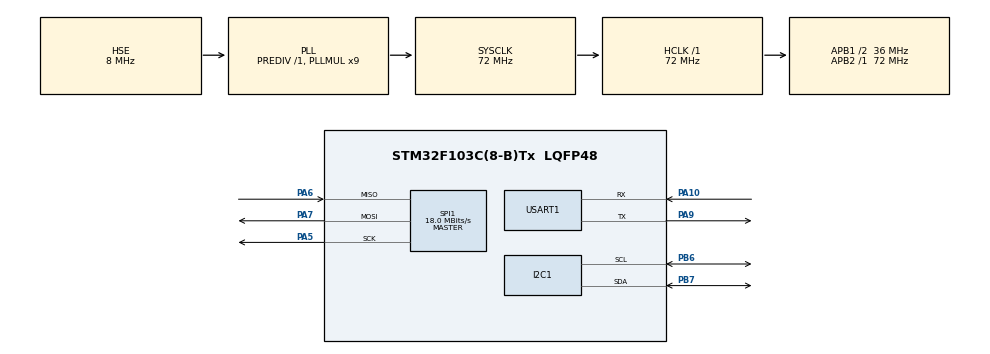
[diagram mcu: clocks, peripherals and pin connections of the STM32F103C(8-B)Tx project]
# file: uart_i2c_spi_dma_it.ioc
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Dma.I2C1_RX.0.Direction=DMA_PERIPH_TO_MEMORY
Dma.I2C1_RX.0.Instance=DMA1_Channel7
Dma.I2C1_RX.0.MemDataAlignment=DMA_MDATAALIGN_BYTE
Dma.I2C1_RX.0.MemInc=DMA_MINC_ENABLE
Dma.I2C1_RX.0.Mode=DMA_NORMAL
Dma.I2C1_RX.0.PeriphDataAlignment=DMA_PDATAALIGN_BYTE
Dma.I2C1_RX.0.PeriphInc=DMA_PINC_DISABLE
Dma.I2C1_RX.0.Priority=DMA_PRIORITY_LOW
Dma.I2C1_TX.1.Direction=DMA_MEMORY_TO_PERIPH
Dma.I2C1_TX.1.Instance=DMA1_Channel6
Dma.I2C1_TX.1.MemDataAlignment=DMA_MDATAALIGN_BYTE
Dma.I2C1_TX.1.MemInc=DMA_MINC_ENABLE
Dma.I2C1_TX.1.Mode=DMA_NORMAL
Dma.I2C1_TX.1.PeriphDataAlignment=DMA_PDATAALIGN_BYTE
Dma.I2C1_TX.1.PeriphInc=DMA_PINC_DISABLE
Dma.I2C1_TX.1.Priority=DMA_PRIORITY_LOW
Dma.Request0=I2C1_RX
Dma.Request1=I2C1_TX
Dma.Request2=USART1_RX
Dma.Request3=USART1_TX
Dma.Request4=SPI1_RX
Dma.Request5=SPI1_TX
Dma.SPI1_RX.4.Direction=DMA_PERIPH_TO_MEMORY
Dma.SPI1_RX.4.Instance=DMA1_Channel2
Dma.SPI1_RX.4.MemDataAlignment=DMA_MDATAALIGN_BYTE
Dma.SPI1_RX.4.MemInc=DMA_MINC_ENABLE
Dma.SPI1_RX.4.Mode=DMA_NORMAL
Dma.SPI1_RX.4.PeriphDataAlignment=DMA_PDATAALIGN_BYTE
Dma.SPI1_RX.4.PeriphInc=DMA_PINC_DISABLE
Dma.SPI1_RX.4.Priority=DMA_PRIORITY_LOW
Dma.SPI1_TX.5.Direction=DMA_MEMORY_TO_PERIPH
Dma.SPI1_TX.5.Instance=DMA1_Channel3
Dma.SPI1_TX.5.MemDataAlignment=DMA_MDATAALIGN_BYTE
Dma.SPI1_TX.5.MemInc=DMA_MINC_ENABLE
Dma.SPI1_TX.5.Mode=DMA_NORMAL
Dma.SPI1_TX.5.PeriphDataAlignment=DMA_PDATAALIGN_BYTE
Dma.SPI1_TX.5.PeriphInc=DMA_PINC_DISABLE
Dma.SPI1_TX.5.Priority=DMA_PRIORITY_LOW
Dma.USART1_RX.2.Direction=DMA_PERIPH_TO_MEMORY
Dma.USART1_RX.2.Instance=DMA1_Channel5
Dma.USART1_RX.2.MemDataAlignment=DMA_MDATAALIGN_BYTE
Dma.USART1_RX.2.MemInc=DMA_MINC_ENABLE
Dma.USART1_RX.2.Mode=DMA_NORMAL
Dma.USART1_RX.2.PeriphDataAlignment=DMA_PDATAALIGN_BYTE
Dma.USART1_RX.2.PeriphInc=DMA_PINC_DISABLE
Dma.USART1_RX.2.Priority=DMA_PRIORITY_LOW
Dma.USART1_TX.3.Direction=DMA_MEMORY_TO_PERIPH
Dma.USART1_TX.3.Instance=DMA1_Channel4
Dma.USART1_TX.3.MemDataAlignment=DMA_MDATAALIGN_BYTE
Dma.USART1_TX.3.MemInc=DMA_MINC_ENABLE
Dma.USART1_TX.3.Mode=DMA_NORMAL
Dma.USART1_TX.3.PeriphDataAlignment=DMA_PDATAALIGN_BYTE
Dma.USART1_TX.3.PeriphInc=DMA_PINC_DISABLE
Dma.USART1_TX.3.Priority=DMA_PRIORITY_LOW
Mcu.Family=STM32F1
Mcu.Name=STM32F103C(8-B)Tx
Mcu.Package=LQFP48
NVIC.DMA1_Channel2_IRQn=true\:0\:0\:false\:false\:true\:false\:true\:true
NVIC.DMA1_Channel3_IRQn=true\:0\:0\:false\:false\:true\:false\:true\:true
NVIC.DMA1_Channel4_IRQn=true\:0\:0\:false\:false\:true\:false\:true\:true
NVIC.DMA1_Channel5_IRQn=true\:0\:0\:false\:false\:true\:false\:true\:true
NVIC.DMA1_Channel6_IRQn=true\:0\:0\:false\:false\:true\:false\:true\:true
NVIC.DMA1_Channel7_IRQn=true\:0\:0\:false\:false\:true\:false\:true\:true
NVIC.I2C1_EV_IRQn=true\:0\:0\:false\:false\:true\:true\:true\:true
NVIC.PriorityGroup=NVIC_PRIORITYGROUP_4
NVIC.SPI1_IRQn=true\:0\:0\:false\:false\:true\:true\:true\:true
NVIC.USART1_IRQn=true\:0\:0\:false\:false\:true\:true\:true\:true
PA10.Mode=Asynchronous
PA10.Signal=USART1_RX
PA13.Mode=Serial_Wire
PA13.Signal=SYS_JTMS-SWDIO
PA14.Mode=Serial_Wire
PA14.Signal=SYS_JTCK-SWCLK
PA5.Mode=Full_Duplex_Master
PA5.Signal=SPI1_SCK
PA6.Mode=Full_Duplex_Master
PA6.Signal=SPI1_MISO
PA7.Mode=Full_Duplex_Master
PA7.Signal=SPI1_MOSI
PA9.Mode=Asynchronous
PA9.Signal=USART1_TX
PB6.Mode=I2C
PB6.Signal=I2C1_SCL
PB7.Mode=I2C
PB7.Signal=I2C1_SDA
PD0-OSC_IN.Mode=HSE-External-Oscillator
PD0-OSC_IN.Signal=RCC_OSC_IN
PD1-OSC_OUT.Mode=HSE-External-Oscillator
PD1-OSC_OUT.Signal=RCC_OSC_OUT
ProjectManager.HeapSize=0x200
ProjectManager.StackSize=0x400
ProjectManager.TargetToolchain=Makefile
RCC.AHBFreq_Value=72000000
RCC.APB1CLKDivider=RCC_HCLK_DIV2
RCC.APB1Freq_Value=36000000
RCC.APB1TimFreq_Value=72000000
RCC.APB2Freq_Value=72000000
RCC.APB2TimFreq_Value=72000000
RCC.HCLKFreq_Value=72000000
RCC.PLLMUL=RCC_PLL_MUL9
RCC.PLLSourceVirtual=RCC_PLLSOURCE_HSE
RCC.SYSCLKFreq_VALUE=72000000
RCC.SYSCLKSource=RCC_SYSCLKSOURCE_PLLCLK
RCC.USBFreq_Value=72000000
SPI1.BaudRatePrescaler=SPI_BAUDRATEPRESCALER_4
SPI1.CalculateBaudRate=18.0 MBits/s
SPI1.Direction=SPI_DIRECTION_2LINES
SPI1.Mode=SPI_MODE_MASTER
SPI1.VirtualType=VM_MASTER
USART1.VirtualMode=VM_ASYNC
board=custom

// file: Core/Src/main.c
/* USER CODE BEGIN Header */
/**
 ******************************************************************************
 * @file           : main.c
 * @brief          : Main program body
 ******************************************************************************
 * @attention
 *
 * Copyright (c) 2024 STMicroelectronics.
 * All rights reserved.
 *
 * This software is licensed under terms that can be found in the LICENSE file
 * in the root directory of this software component.
 * If no LICENSE file comes with this software, it is provided AS-IS.
 *
 ******************************************************************************
 */
/* USER CODE END Header */
#include "main.h"
#include "dma.h"
#include "i2c.h"
#include "spi.h"
#include "usart.h"
#include "gpio.h"

/* USER CODE BEGIN Includes */
#include <string.h>
#include "uart_printf.h"
/* USER CODE END Includes */

/* USER CODE BEGIN PTD */
#define AHT20 0x38
#define BMP280 0x77 << 1
#define AT24C256 0xA0

#define AT24C256_NORMAL_TEST 1
#define AT24C256_IT_TEST 0
#define AT24C256_DMA_TEST 0
/* USER CODE END PTD */

void SystemClock_Config(void);

int main(void)
{

  /* MCU Configuration--------------------------------------------------------*/

  /* Reset of all peripherals, Initializes the Flash interface and the Systick. */
  // 初始化HAL库
  HAL_Init();

  /* Configure the system clock */
  // 配置system clock pll HCLK PCLK1 PCK2
  SystemClock_Config();

  /* Initialize all configured peripherals */
  MX_GPIO_Init();
  // 初始化DMA
  MX_DMA_Init();

  MX_I2C1_Init();
  // 初始化串口
  MX_USART1_UART_Init();
  // 初始化SPI
  MX_SPI1_Init();

  /* Infinite loop */
  /* USER CODE BEGIN WHILE */

  char TxData[] = "TEST FOR AT24C256 \r\n";

  // HAL_UART_Transmit_IT(&huart1, (uint8_t *)TxData, strlen(TxData));
  uart_printf_init();

  while (1)
  {
    /* USER CODE END WHILE */
    // HAL_UART_Transmit_IT(&huart1, (uint8_t *)TxData, strlen(TxData));
    uart_printf(TxData, NULL, 0);
    HAL_Delay(1000);

    uint8_t I2CTXdata[] = {0x00, 0x0F, 0xE2, 0xA3, 0xB8, 0x77, 0xfa, 0xaE, 0xBA};
    HAL_GPIO_WritePin(GPIOC, GPIO_PIN_13, GPIO_PIN_SET);
    HAL_Delay(1000);
    HAL_GPIO_WritePin(GPIOC, GPIO_PIN_13, GPIO_PIN_RESET);
#if AT24C256_NORMAL_TEST
    uart_printf("NORMAL TEST FOR AT24C256 \r\n", NULL, 0);

    uart_printf("AT24C256 write data:", &I2CTXdata[1], 8);

    HAL_I2C_Master_Transmit(&hi2c1, AT24C256, I2CTXdata, 9, 100);

    HAL_Delay(100);
    uint8_t I2CRXdata[8] = {};
    HAL_I2C_Master_Transmit(&hi2c1, AT24C256, I2CTXdata, 1, 100);
    HAL_I2C_Master_Receive(&hi2c1, AT24C256, &I2CRXdata[0], 8, 100);

    uart_printf("AT24C256 read data:", &I2CRXdata[0], 8);
#endif
    // HAL_I2C_Master_Receive(&hi2c1, BMP280, &data, 1, 100);
    // uart_printf("i2c rceive data", &data);
    //  uint8_t buffdata[1000];
    // uart_fifo_get(&buffdata[0], sizeof(buffdata));
    // HAL_Delay(1000);
    // HAL_UART_Transmit(&huart1, buffdata, sizeof(buffdata), 100);
    /* USER CODE BEGIN 3 */
    // HAL_I2C_Master_Transmit(&hi2c1, 0x38, (uint8_t*)TxData, strlen(TxData), 100);

    // HAL_I2C_Master_Transmit_DMA(&hi2c1, 0x38,(uint8_t*)TxData,strlen(TxData));
  }
  /* USER CODE END 3 */
}

void SystemClock_Config(void)
{
  // 内部/外部振荡器结构体
  RCC_OscInitTypeDef RCC_OscInitStruct = {0};
  // RCC系统、AHB总线和APB总线的时钟配置结构定义
  RCC_ClkInitTypeDef RCC_ClkInitStruct = {0};

  /** Initializes the RCC Oscillators according to the specified parameters
   * in the RCC_OscInitTypeDef structure.
   */
  // 配置时钟结构体
  // 配置外置时钟
  RCC_OscInitStruct.OscillatorType = RCC_OSCILLATORTYPE_HSE;
  // 开启外置时钟
  RCC_OscInitStruct.HSEState = RCC_HSE_ON;
  // HSE时钟预分频器 设置为不分频 RCC_CFGR bit17
  RCC_OscInitStruct.HSEPredivValue = RCC_HSE_PREDIV_DIV1;
  // 开启内置时钟
  RCC_OscInitStruct.HSIState = RCC_HSI_ON;
  // 使用PLL
  RCC_OscInitStruct.PLL.PLLState = RCC_PLL_ON;
  // PLL时钟源是HSE
  RCC_OscInitStruct.PLL.PLLSource = RCC_PLLSOURCE_HSE;
  // PLL倍频9倍
  RCC_OscInitStruct.PLL.PLLMUL = RCC_PLL_MUL9;

  // 配置HSE、PLL
  if (HAL_RCC_OscConfig(&RCC_OscInitStruct) != HAL_OK)
  {
    Error_Handler();
  }

  /** Initializes the CPU, AHB and APB buses clocks
   */
  // 使能HCLK、SYSCLK、PCLK1、PCLK2
  RCC_ClkInitStruct.ClockType = RCC_CLOCKTYPE_HCLK | RCC_CLOCKTYPE_SYSCLK | RCC_CLOCKTYPE_PCLK1 | RCC_CLOCKTYPE_PCLK2;
  // 系统时钟使用PLL
  RCC_ClkInitStruct.SYSCLKSource = RCC_SYSCLKSOURCE_PLLCLK;
  // AHB预分频器不分频
  RCC_ClkInitStruct.AHBCLKDivider = RCC_SYSCLK_DIV1;
  // APB1预分频器2分频
  RCC_ClkInitStruct.APB1CLKDivider = RCC_HCLK_DIV2;
  // APB2预分频器不分频
  RCC_ClkInitStruct.APB2CLKDivider = RCC_HCLK_DIV1;

  if (HAL_RCC_ClockConfig(&RCC_ClkInitStruct, FLASH_LATENCY_2) != HAL_OK)
  {
    Error_Handler();
  }
}

void Error_Handler(void)
{
  __disable_irq();
  while (1)
  {
  }
}
